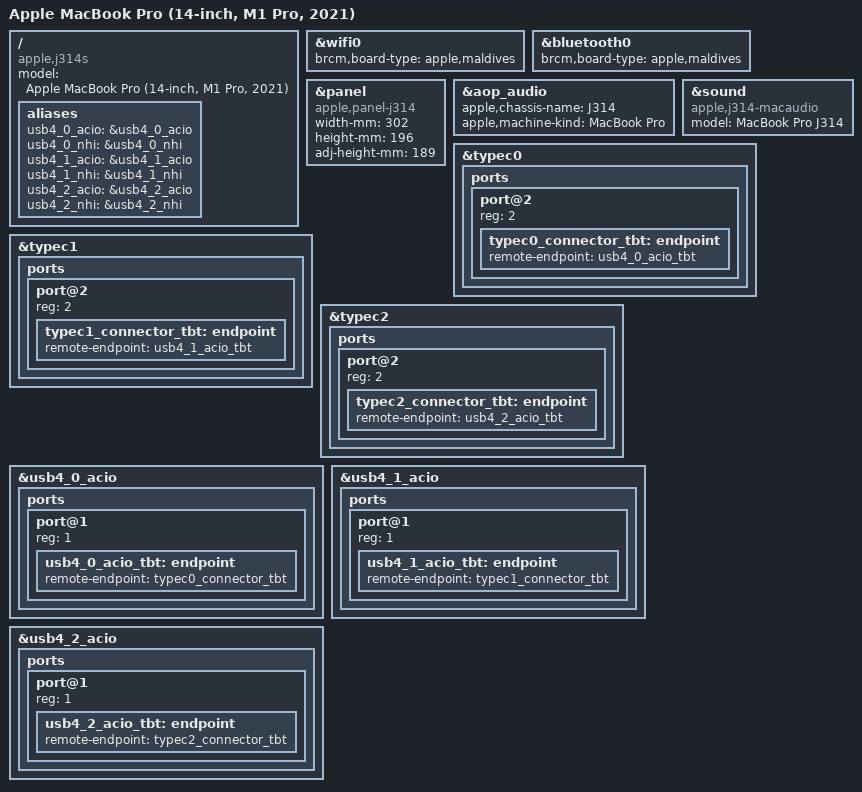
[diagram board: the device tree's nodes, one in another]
// SPDX-License-Identifier: GPL-2.0+ OR MIT
/*
 * MacBook Pro (14-inch, M1 Pro, 2021)
 *
 * target-type: J314s
 *
 * Copyright The Asahi Linux Contributors
 */

/dts-v1/;

#include "t6000.dtsi"
#include "t600x-j314-j316.dtsi"

/ {
	compatible = "apple,j314s", "apple,t6000", "apple,arm-platform";
	model = "Apple MacBook Pro (14-inch, M1 Pro, 2021)";
};

&wifi0 {
	brcm,board-type = "apple,maldives";
};

&bluetooth0 {
	brcm,board-type = "apple,maldives";
};

&panel {
	compatible = "apple,panel-j314", "apple,panel-mini-led", "apple,panel";
	width-mm = <302>;
	height-mm = <196>;
	adj-height-mm = <189>;
};

&aop_audio {
	apple,chassis-name = "J314";
	apple,machine-kind = "MacBook Pro";
};

&sound {
	compatible = "apple,j314-macaudio", "apple,macaudio";
	model = "MacBook Pro J314";
};

/* USB4 / Thunderbolt routers map one-to-one to the three USB-C connectors. */
/ {
	aliases {
		usb4_0_acio = &usb4_0_acio;
		usb4_0_nhi = &usb4_0_nhi;
		usb4_1_acio = &usb4_1_acio;
		usb4_1_nhi = &usb4_1_nhi;
		usb4_2_acio = &usb4_2_acio;
		usb4_2_nhi = &usb4_2_nhi;
	};
};

&typec0 {
	ports {
		port@2 {
			reg = <2>;
			typec0_connector_tbt: endpoint {
				remote-endpoint = <&usb4_0_acio_tbt>;
			};
		};
	};
};

&typec1 {
	ports {
		port@2 {
			reg = <2>;
			typec1_connector_tbt: endpoint {
				remote-endpoint = <&usb4_1_acio_tbt>;
			};
		};
	};
};

&typec2 {
	ports {
		port@2 {
			reg = <2>;
			typec2_connector_tbt: endpoint {
				remote-endpoint = <&usb4_2_acio_tbt>;
			};
		};
	};
};

&usb4_0_acio {
	ports {
		#address-cells = <1>;
		#size-cells = <0>;

		port@1 {
			reg = <1>;
			usb4_0_acio_tbt: endpoint {
				remote-endpoint = <&typec0_connector_tbt>;
			};
		};
	};
};

&usb4_1_acio {
	ports {
		#address-cells = <1>;
		#size-cells = <0>;

		port@1 {
			reg = <1>;
			usb4_1_acio_tbt: endpoint {
				remote-endpoint = <&typec1_connector_tbt>;
			};
		};
	};
};

&usb4_2_acio {
	ports {
		#address-cells = <1>;
		#size-cells = <0>;

		port@1 {
			reg = <1>;
			usb4_2_acio_tbt: endpoint {
				remote-endpoint = <&typec2_connector_tbt>;
			};
		};
	};
};
